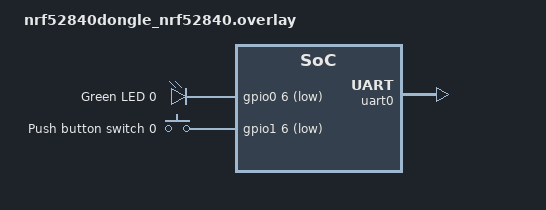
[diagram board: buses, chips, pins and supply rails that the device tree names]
/ {
    leds {
        compatible = "gpio-leds";
        led0_green: led_0 {
			gpios = <&gpio0 6 GPIO_ACTIVE_LOW>;
			label = "Green LED 0";
		};
       
    };
    aliases {
        led0 = &led0_green;
        sw0 = &button0;
    };

    uart0 {
        status = "okay";
    };

buttons {
    compatible = "gpio-keys";
    button0: button_0 {
        gpios = <&gpio1 6 (GPIO_PULL_UP | GPIO_ACTIVE_LOW)>;
        label = "Push button switch 0";
        zephyr,code = <INPUT_KEY_0>;
        status = "okay";
    };
};

};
